# RK3399-AP register map
File version: 1
CPU: CA7 r0p1, little endian, MPU, FPU, I-cache, D-cache, VTOR, 4 interrupt priority bits, 0 interrupts
Registers are 32-bit, read-write, reset 0x0 unless marked. A register's access mark holds for its fields unless they carry their own. Offsets are from the block's base; [hi:lo] are bit positions.

## CIC
Base 0xFF620000
0x00 CIC_CTRL0 access not given — DDR Controller LP Interface Control Register 0
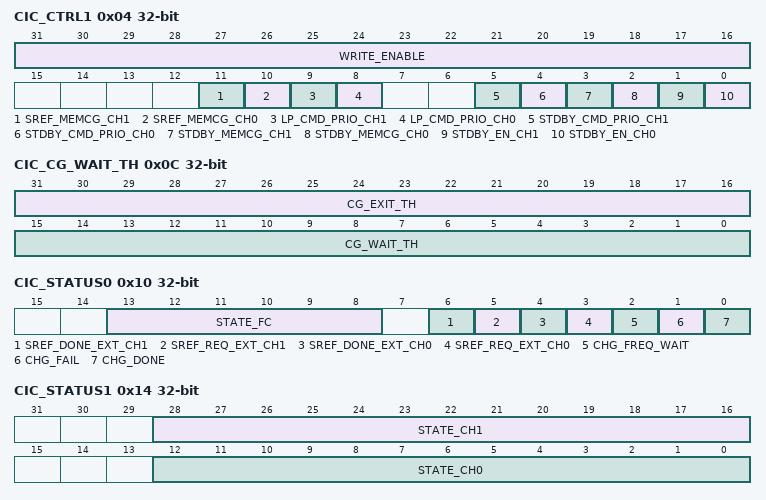
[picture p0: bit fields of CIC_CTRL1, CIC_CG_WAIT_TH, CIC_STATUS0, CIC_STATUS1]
0x04 CIC_CTRL1 — DDR Controller LP Interface Control Register 1
  [31:16] WRITE_ENABLE — bit0~15 write enable When bit 16=1, bit 0 can be written by software. When bit 16=0, bit 0 cannot be written by software; When bit 17=1, bit 1 can be written by software. When bit 17=0, bit 1 cannot be written by software; ...... When bit 31=1, bit 15 can be written by software. When bit 31=0, bit 15 cannot be written by software;
  [11] SREF_MEMCG_CH1 — Channel 1 memory clock gating in self-refresh 1\'b0: memory is not clock gated in external self-refresh 1\'b1: memory is clock gated in external self-refresh
  [10] SREF_MEMCG_CH0 — Channel 0 memory clock gating in self-refresh 1\'b0: memory is not clock gated in external self-refresh 1\'b1: memory is clock gated in external self-refresh
  [9] LP_CMD_PRIO_CH1 — Channel 1 LP command priority in external self-refresh mode 1\'b0: don\'t issue priority request when enter external self-refresh 1\'b1: issue priority request when enter external self-refresh
  [8] LP_CMD_PRIO_CH0 — Channel 0 LP command priority in external self-refresh mode 1\'b0: don\'t issue priority request when enter external self-refresh 1\'b1: issue priority request when enter external self-refresh
  [5] STDBY_CMD_PRIO_CH1 — Channel 1 LP command priority in standby mode 1\'b0: don\'t issue priority request when enter standby mode 1\'b1: issue priority request when enter standby mode
  [4] STDBY_CMD_PRIO_CH0 — Channel 0 LP command priority in standby mode 1\'b0: don\'t issue priority request when enter standby mode 1\'b1: issue priority request when enter standby mode
  [3] STDBY_MEMCG_CH1 — Channel 1 memory clock gating in standby mode 1\'b0: memory is not clock gated when in standby mode 1\'b1: memory is clock gated when in standby mode
  [2] STDBY_MEMCG_CH0 — Channel 0 memory clock gating in standby mode 1\'b0: memory is not clock gated when in standby mode 1\'b1: memory is clock gated when in standby mode
  [1] STDBY_EN_CH1 — Channel 1 standby mode enable 1\'b0: disable 1\'b1: enable
  [0] STDBY_EN_CH0 — Channel 0 standby mode enable 1\'b0: disable 1\'b1: enable
0x08 CIC_IDLE_TH — DDR Controller LP Interface Idle Threshold in standby mode
  [15:0] IDLE_TH — Idle counter threshold in standby mode
0x0C CIC_CG_WAIT_TH — DDR Controller LP Interface CG Wait Threshold in standby mode
  [31:16] CG_EXIT_TH — Clock gating exit counter threshold in standby mode
  [15:0] CG_WAIT_TH — Clock gating wait counter threshold in standby mode
0x10 CIC_STATUS0 ro — DDR Controller LP Interface Status Register 0
  [13:8] STATE_FC — Frequency change state machine
  [6] SREF_DONE_EXT_CH1 — Channel 1 external self-refresh done
  [5] SREF_REQ_EXT_CH1 — Channel 1 external self-refresh request
  [4] SREF_DONE_EXT_CH0 — Channel 0 external self-refresh done
  [3] SREF_REQ_EXT_CH0 — Channel 0 external self-refresh request
  [2] CHG_FREQ_WAIT — Frequency change wait
  [1] CHG_FAIL — Frequency change fail
  [0] CHG_DONE — Frequency change done
0x14 CIC_STATUS1 ro — DDR Controller LP Interface Status Register 1
  [28:16] STATE_CH1 — Channel 1 external self-refresh and standby mode state machine
  [12:0] STATE_CH0 — Channel 0 external self-refresh and standby mode state machine
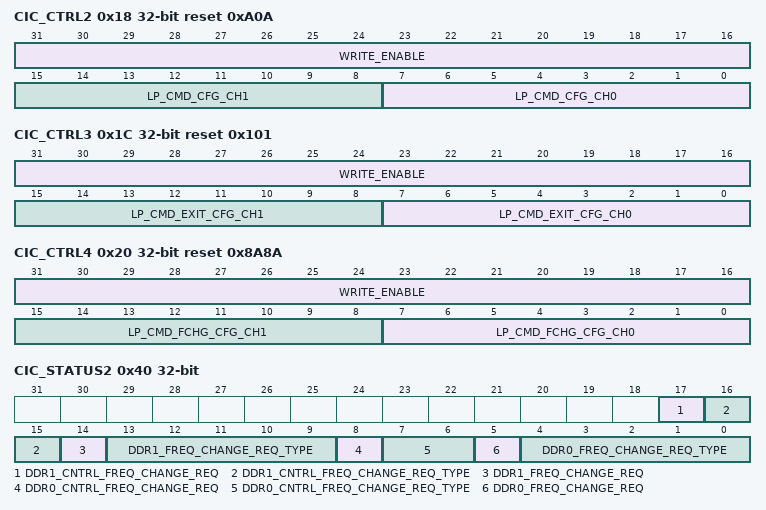
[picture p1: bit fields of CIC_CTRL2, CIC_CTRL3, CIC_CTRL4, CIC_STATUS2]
0x18 CIC_CTRL2 reset 0xA0A — DDR Controller LP Interface Control Register 2
  [31:16] WRITE_ENABLE — bit0~15 write enable When bit 16=1, bit 0 can be written by software. When bit 16=0, bit 0 cannot be written by software; When bit 17=1, bit 1 can be written by software. When bit 17=0, bit 1 cannot be written by software; ...... When bit 31=1, bit 15 can be written by software. When bit 31=0, bit 15 cannot be written by software;
  [15:8] LP_CMD_CFG_CH1 — Channel 1 external self-refresh enter command
  [7:0] LP_CMD_CFG_CH0 — Channel 0 external self-refresh enter command
0x1C CIC_CTRL3 reset 0x101 — DDR Controller LP Interface Control Register 3
  [31:16] WRITE_ENABLE — bit0~15 write enable When bit 16=1, bit 0 can be written by software. When bit 16=0, bit 0 cannot be written by software; When bit 17=1, bit 1 can be written by software. When bit 17=0, bit 1 cannot be written by software; ...... When bit 31=1, bit 15 can be written by software. When bit 31=0, bit 15 cannot be written by software;
  [15:8] LP_CMD_EXIT_CFG_CH1 — Channel 1 external self-refresh exit command
  [7:0] LP_CMD_EXIT_CFG_CH0 — Channel 0 external self-refresh exit command
0x20 CIC_CTRL4 reset 0x8A8A — DDR Controller LP Interface Control Register 4
  [31:16] WRITE_ENABLE — bit0~15 write enable When bit 16=1, bit 0 can be written by software. When bit 16=0, bit 0 cannot be written by software; When bit 17=1, bit 1 can be written by software. When bit 17=0, bit 1 cannot be written by software; ...... When bit 31=1, bit 15 can be written by software. When bit 31=0, bit 15 cannot be written by software;
  [15:8] LP_CMD_FCHG_CFG_CH1 — Channel 1 frequency change enter command
  [7:0] LP_CMD_FCHG_CFG_CH0 — Channel 0 frequency change enter command
0x40 CIC_STATUS2 ro — DDR Controller LP Interface Status Register 2
  [17] DDR1_CNTRL_FREQ_CHANGE_REQ — Channel 1 DDR controller frequency change request
  [16:15] DDR1_CNTRL_FREQ_CHANGE_REQ_TYPE — Channel 1 DDR controller frequency change request type
  [14] DDR1_FREQ_CHANGE_REQ — Channel 1 DDR PHY frequency change request
  [13:9] DDR1_FREQ_CHANGE_REQ_TYPE — Channel 1 DDR PHY frequency change request type
  [8] DDR0_CNTRL_FREQ_CHANGE_REQ — Channel 0 DDR controller frequency change request
  [7:6] DDR0_CNTRL_FREQ_CHANGE_REQ_TYPE — Channel 0 DDR controller frequency change request type
  [5] DDR0_FREQ_CHANGE_REQ — Channel 0 DDR PHY frequency change request
  [4:0] DDR0_FREQ_CHANGE_REQ_TYPE — Channel 0 DDR PHY frequency change request type reserved ip_version DDR monitor IP version
